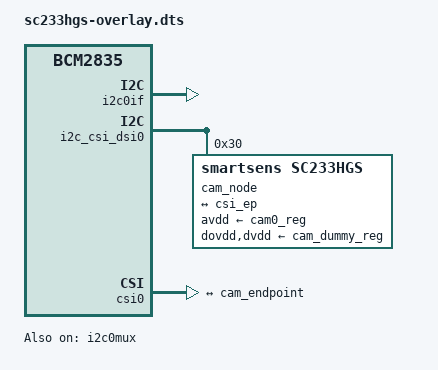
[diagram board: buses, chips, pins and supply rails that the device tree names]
/dts-v1/;
/plugin/;

/*
 * SC233HGS on Raspberry Pi 5 CAM/DISP 0.
 * 4 lanes, 270 MHz link, 27 MHz XCLK. Same mode CameVision Ego streamed.
 */

/ {
	compatible = "brcm,bcm2835";

	fragment@0 {
		target = <&i2c0if>;
		__overlay__ {
			status = "okay";
		};
	};

	fragment@1 {
		target = <&i2c0mux>;
		__overlay__ {
			status = "okay";
		};
	};

	fragment@2 {
		target = <&cam0_clk>;
		__overlay__ {
			status = "okay";
			clock-frequency = <27000000>;
		};
	};

	fragment@3 {
		target = <&i2c_csi_dsi0>;
		__overlay__ {
			#address-cells = <1>;
			#size-cells = <0>;
			status = "okay";

			cam_node: sc233hgs@30 {
				compatible = "smartsens,sc233hgs";
				reg = <0x30>;
				status = "okay";

				clocks = <&cam0_clk>;
				clock-names = "xclk";

				avdd-supply = <&cam0_reg>;
				dovdd-supply = <&cam_dummy_reg>;
				dvdd-supply = <&cam_dummy_reg>;

				rotation = <0>;
				orientation = <2>;

				port {
					cam_endpoint: endpoint {
						clock-lanes = <0>;
						data-lanes = <1 2 3 4>;
						link-frequencies =
							/bits/ 64 <270000000>;
						remote-endpoint = <&csi_ep>;
					};
				};
			};
		};
	};

	fragment@4 {
		target = <&csi0>;
		__overlay__ {
			status = "okay";

			port {
				csi_ep: endpoint {
					remote-endpoint = <&cam_endpoint>;
					clock-lanes = <0>;
					data-lanes = <1 2 3 4>;
				};
			};
		};
	};
};
